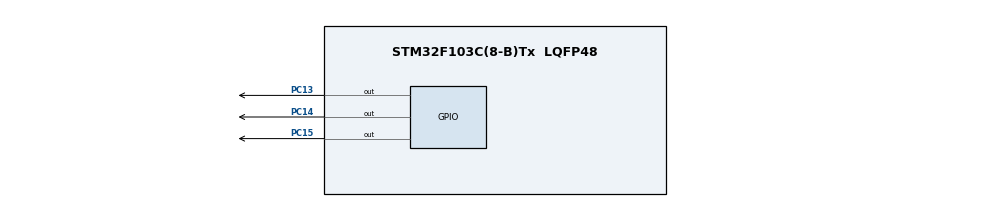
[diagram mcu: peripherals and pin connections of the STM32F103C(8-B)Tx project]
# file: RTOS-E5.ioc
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FREERTOS.Tasks01=defaultTask,24,128,StartDefaultTask,Default,NULL,Dynamic,NULL,NULL;grreenLed,16,128,GreenLed,Default,NULL,Dynamic,NULL,NULL;redLed,25,128,RedLed,Default,NULL,Dynamic,NULL,NULL
Mcu.Family=STM32F1
Mcu.Name=STM32F103C(8-B)Tx
Mcu.Package=LQFP48
NVIC.PriorityGroup=NVIC_PRIORITYGROUP_4
NVIC.TIM4_IRQn=true\:15\:0\:false\:false\:true\:false\:false\:true\:true
NVIC.TimeBase=TIM4_IRQn
NVIC.TimeBaseIP=TIM4
PA13.Mode=Trace_Asynchronous_SW
PA13.Signal=SYS_JTMS-SWDIO
PA14.Mode=Trace_Asynchronous_SW
PA14.Signal=SYS_JTCK-SWCLK
PB3.Mode=Trace_Asynchronous_SW
PB3.Signal=SYS_JTDO-TRACESWO
PC13-TAMPER-RTC.Signal=GPIO_Output
PC14-OSC32_IN.Signal=GPIO_Output
PC15-OSC32_OUT.Signal=GPIO_Output
ProjectManager.HeapSize=0x200
ProjectManager.StackSize=0x400
ProjectManager.TargetToolchain=STM32CubeIDE
RCC.APB1Freq_Value=8000000
RCC.APB2Freq_Value=8000000
VP_FREERTOS_VS_CMSIS_V2.Mode=CMSIS_V2
VP_SYS_VS_tim4.Mode=TIM4
board=custom

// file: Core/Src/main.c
/* USER CODE BEGIN Header */
/**
  ******************************************************************************
  * @file           : main.c
  * @brief          : Main program body
  ******************************************************************************
  * @attention
  *
  * Copyright (c) 2024 STMicroelectronics.
  * All rights reserved.
  *
  * This software is licensed under terms that can be found in the LICENSE file
  * in the root directory of this software component.
  * If no LICENSE file comes with this software, it is provided AS-IS.
  *
  ******************************************************************************
  */
/* USER CODE END Header */
#include "main.h"
#include "cmsis_os.h"
#include "task.h"

/* USER CODE BEGIN PD */
#define GREEN_LED_PIN GPIO_PIN_14
#define RED_LED_PIN GPIO_PIN_15
#define ORANGE_LED_PIN GPIO_PIN_0
#define BLUE_LED_PIN GPIO_PIN_13
#define LED_GPIO_PORT GPIOC

/* USER CODE END PD */

/* Definitions for defaultTask */
osThreadId_t defaultTaskHandle;
const osThreadAttr_t defaultTask_attributes = {
  .name = "defaultTask",
  .stack_size = 128 * 4,
  .priority = (osPriority_t) osPriorityNormal,
};
/* Definitions for greenLed */
osThreadId_t greenLedHandle;
const osThreadAttr_t greenLed_attributes = {
  .name = "greenLed",
  .stack_size = 128 * 4,
  .priority = (osPriority_t) osPriorityNormal,
};
/* Definitions for redLed */
osThreadId_t redLedHandle;
const osThreadAttr_t redLed_attributes = {
  .name = "redLed",
  .stack_size = 128 * 4,
  .priority = (osPriority_t) osPriorityNormal,
};
/* Definitions for orangeLed */
osThreadId_t orangeLedHandle;
const osThreadAttr_t orangeLed_attributes = {
  .name = "orangeLed",
  .stack_size = 128 * 4,
  .priority = (osPriority_t) osPriorityAboveNormal,
};
/* USER CODE BEGIN PV */
uint8_t StartFlag; // 1 means Up, 0 means Down
volatile uint8_t RedFlag; // 1 means Up, 0 means Down
volatile uint8_t GreenFlag; // 1 means Up, 0 means Down
/* USER CODE END PV */

void SystemClock_Config(void);
static void MX_GPIO_Init(void);
void StartDefaultTask(void *argument);
void GreenLed(void *argument);
void RedLed(void *argument);
void OrangeLed(void *argument);

int main(void)
{

  /* USER CODE BEGIN 1 */
	StartFlag = 1;
	GreenFlag = 1;
	RedFlag = 1;
  /* USER CODE END 1 */

  /* MCU Configuration--------------------------------------------------------*/

  /* Reset of all peripherals, Initializes the Flash interface and the Systick. */
  HAL_Init();

  /* Configure the system clock */
  SystemClock_Config();

  /* Initialize all configured peripherals */
  MX_GPIO_Init();
  HAL_GPIO_WritePin(GPIOC, GPIO_PIN_13, GPIO_PIN_SET);

  /* Init scheduler */
  osKernelInitialize();

  /* Create the thread(s) */
  /* creation of defaultTask */
  defaultTaskHandle = osThreadNew(StartDefaultTask, NULL, &defaultTask_attributes);

  /* creation of greenLed */
  greenLedHandle = osThreadNew(GreenLed, NULL, &greenLed_attributes);

  /* creation of redLed */
  redLedHandle = osThreadNew(RedLed, NULL, &redLed_attributes);

  /* creation of orangeLed */
  orangeLedHandle = osThreadNew(OrangeLed, NULL, &orangeLed_attributes);

  /* Start scheduler */
  osKernelStart();

  /* We should never get here as control is now taken by the scheduler */

  /* Infinite loop */
  while (1)
  {

  }
}

void SystemClock_Config(void)
{
  RCC_OscInitTypeDef RCC_OscInitStruct = {0};
  RCC_ClkInitTypeDef RCC_ClkInitStruct = {0};

  /** Initializes the RCC Oscillators according to the specified parameters
  * in the RCC_OscInitTypeDef structure.
  */
  RCC_OscInitStruct.OscillatorType = RCC_OSCILLATORTYPE_HSI;
  RCC_OscInitStruct.HSIState = RCC_HSI_ON;
  RCC_OscInitStruct.HSICalibrationValue = RCC_HSICALIBRATION_DEFAULT;
  RCC_OscInitStruct.PLL.PLLState = RCC_PLL_NONE;
  if (HAL_RCC_OscConfig(&RCC_OscInitStruct) != HAL_OK)
  {
    Error_Handler();
  }

  /** Initializes the CPU, AHB and APB buses clocks
  */
  RCC_ClkInitStruct.ClockType = RCC_CLOCKTYPE_HCLK|RCC_CLOCKTYPE_SYSCLK
                              |RCC_CLOCKTYPE_PCLK1|RCC_CLOCKTYPE_PCLK2;
  RCC_ClkInitStruct.SYSCLKSource = RCC_SYSCLKSOURCE_HSI;
  RCC_ClkInitStruct.AHBCLKDivider = RCC_SYSCLK_DIV1;
  RCC_ClkInitStruct.APB1CLKDivider = RCC_HCLK_DIV1;
  RCC_ClkInitStruct.APB2CLKDivider = RCC_HCLK_DIV1;

  if (HAL_RCC_ClockConfig(&RCC_ClkInitStruct, FLASH_LATENCY_0) != HAL_OK)
  {
    Error_Handler();
  }
}

static void MX_GPIO_Init(void)
{
  GPIO_InitTypeDef GPIO_InitStruct = {0};

  /* GPIO Ports Clock Enable */
  __HAL_RCC_GPIOC_CLK_ENABLE();
  __HAL_RCC_GPIOA_CLK_ENABLE();
  __HAL_RCC_GPIOB_CLK_ENABLE();

  /*Configure GPIO pin Output Level */
  HAL_GPIO_WritePin(GPIOC, GPIO_PIN_13|GPIO_PIN_14|GPIO_PIN_15, GPIO_PIN_RESET);

  /*Configure GPIO pin Output Level */
  HAL_GPIO_WritePin(GPIOA, GPIO_PIN_0, GPIO_PIN_RESET);

  /*Configure GPIO pins : PC13 PC14 PC15 */
  GPIO_InitStruct.Pin = GPIO_PIN_13|GPIO_PIN_14|GPIO_PIN_15;
  GPIO_InitStruct.Mode = GPIO_MODE_OUTPUT_PP;
  GPIO_InitStruct.Pull = GPIO_NOPULL;
  GPIO_InitStruct.Speed = GPIO_SPEED_FREQ_LOW;
  HAL_GPIO_Init(GPIOC, &GPIO_InitStruct);

  /*Configure GPIO pin : PA0 */
  GPIO_InitStruct.Pin = GPIO_PIN_0;
  GPIO_InitStruct.Mode = GPIO_MODE_OUTPUT_PP;
  GPIO_InitStruct.Pull = GPIO_NOPULL;
  GPIO_InitStruct.Speed = GPIO_SPEED_FREQ_LOW;
  HAL_GPIO_Init(GPIOA, &GPIO_InitStruct);

}

void StartDefaultTask(void *argument)
{
  for(;;)
  {
    osDelay(1);
  }
}

void GreenLed(void *argument)
{
  /* USER CODE BEGIN GreenLed */
  /* Infinite loop */
	for (;;)
	  {
	    /* Turn on Green LED */
	    HAL_GPIO_WritePin(LED_GPIO_PORT, GREEN_LED_PIN, GPIO_PIN_SET);

	    /* Access shared data (critical section) */
	    taskENTER_CRITICAL();
	    AccessSharedData();
	    taskEXIT_CRITICAL();

	    /* Turn off Green LED */
	    HAL_GPIO_WritePin(LED_GPIO_PORT, GREEN_LED_PIN, GPIO_PIN_RESET);

	    /* Delay */
	    osDelay(200);
  }
  /* USER CODE END GreenLed */
}

void RedLed(void *argument)
{
  /* USER CODE BEGIN RedLed */
  /* Infinite loop */
	for (;;)
	  {
	    /* Turn on Red LED */
	    HAL_GPIO_WritePin(LED_GPIO_PORT, RED_LED_PIN, GPIO_PIN_SET);

	    /* Access shared data (critical section) */
	    taskENTER_CRITICAL();
	    AccessSharedData();
	    taskEXIT_CRITICAL();

	    /* Turn off Red LED */
	    HAL_GPIO_WritePin(LED_GPIO_PORT, RED_LED_PIN, GPIO_PIN_RESET);

	    /* Delay */
	    osDelay(550);
  }
  /* USER CODE END RedLed */
}

void AccessSharedData(void) {
    if (StartFlag == 1) {
        // Set Start flag to Down to indicate resource is in use
        StartFlag = 0;
    } else {
        // Resource contention: Turn on Blue LED
        HAL_GPIO_WritePin(GPIOC, GPIO_PIN_13, GPIO_PIN_RESET);
    }

    // Simulate read/write operations with a delay of 500 milliseconds
    SimulateReadWriteOperation();

    // Set Start flag back to Up to indicate resource is free
    StartFlag = 1;

    // Turn off Blue LED (if it was turned on during contention)
    HAL_GPIO_WritePin(GPIOC, GPIO_PIN_13, GPIO_PIN_SET);
}

void SimulateReadWriteOperation(void) {
    volatile uint32_t delay_count = 0;
    const uint32_t delay_target = 2000000; // Adjust this value to approximate 500 ms

    // Dummy loop to simulate processing time
    for (delay_count = 0; delay_count < delay_target; delay_count++) {
        __asm("nop"); // No Operation: Keeps the processor busy without changing code behavior
    }
}

void OrangeLed(void *argument)
{
  /* USER CODE BEGIN OrangeLed */
  /* Infinite loop */
	for (;;)
	  {
	    HAL_GPIO_TogglePin(GPIOA, ORANGE_LED_PIN);
	    osDelay(50);
  }
  /* USER CODE END OrangeLed */
}

void HAL_TIM_PeriodElapsedCallback(TIM_HandleTypeDef *htim)
{
  if (htim->Instance == TIM4) {
    HAL_IncTick();
  }
}

void Error_Handler(void)
{
  __disable_irq();
  while (1)
  {
  }
}
